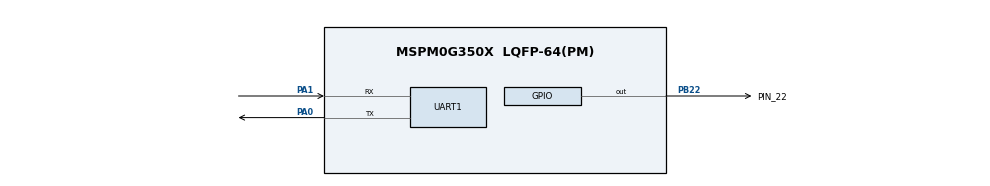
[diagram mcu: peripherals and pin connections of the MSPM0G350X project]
/**
 * @cliArgs --device "MSPM0G350X" --part "Default" --package "LQFP-64(PM)" --product "mspm0_sdk@2.04.00.06"
 * @versions {"tool":"1.22.0+3893"}
 */

/**
 * Import the modules used in this configuration.
 */
const GPIO   = scripting.addModule("/ti/driverlib/GPIO", {}, false);
const GPIO1  = GPIO.addInstance();
const GPIO2  = GPIO.addInstance();
const SYSCTL = scripting.addModule("/ti/driverlib/SYSCTL");
const TIMER  = scripting.addModule("/ti/driverlib/TIMER", {}, false);
const TIMER1 = TIMER.addInstance();
const UART   = scripting.addModule("/ti/driverlib/UART", {}, false);
const UART1  = UART.addInstance();

/**
 * Write custom configuration values to the imported modules.
 */
const divider7       = system.clockTree["PLL_PDIV"];
divider7.divideValue = 2;

const divider9       = system.clockTree["UDIV"];
divider9.divideValue = 2;

const gate7  = system.clockTree["MFCLKGATE"];
gate7.enable = true;

const multiplier2         = system.clockTree["PLL_QDIV"];
multiplier2.multiplyValue = 10;

const mux8       = system.clockTree["HSCLKMUX"];
mux8.inputSelect = "HSCLKMUX_SYSPLL0";

GPIO1.$name                              = "LED1";
GPIO1.port                               = "PORTB";
GPIO1.associatedPins[0].$name            = "PIN_22";
GPIO1.associatedPins[0].internalResistor = "PULL_DOWN";
GPIO1.associatedPins[0].assignedPin      = "22";
GPIO1.associatedPins[0].pin.$assign      = "PB22";

const Board = scripting.addModule("/ti/driverlib/Board", {}, false);

GPIO2.$name                              = "KEY";
GPIO2.port                               = "PORTB";
GPIO2.associatedPins[0].$name            = "PIN_21";
GPIO2.associatedPins[0].direction        = "INPUT";
GPIO2.associatedPins[0].internalResistor = "PULL_UP";
GPIO2.associatedPins[0].assignedPin      = "21";
GPIO2.associatedPins[0].interruptEn      = true;
GPIO2.associatedPins[0].polarity         = "RISE";

SYSCTL.forceDefaultClkConfig = true;
SYSCTL.clockTreeEn           = true;

TIMER1.$name              = "TIMER_0";
TIMER1.timerClkDiv        = 8;
TIMER1.timerStartTimer    = true;
TIMER1.interrupts         = ["ZERO"];
TIMER1.timerClkPrescale   = 250;
TIMER1.timerMode          = "PERIODIC_UP";
TIMER1.timerPeriod        = "1ms";
TIMER1.peripheral.$assign = "TIMG0";

UART1.$name                    = "UART_0";
UART1.uartClkSrc               = "MFCLK";
UART1.targetBaudRate           = 115200;
UART1.enabledInterrupts        = ["RX"];
UART1.peripheral.rxPin.$assign = "PA1";
UART1.peripheral.txPin.$assign = "PA0";
UART1.txPinConfig.$name        = "ti_driverlib_gpio_GPIOPinGeneric0";
UART1.rxPinConfig.$name        = "ti_driverlib_gpio_GPIOPinGeneric1";

/**
 * Pinmux solution for unlocked pins/peripherals. This ensures that minor changes to the automatic solver in a future
 * version of the tool will not impact the pinmux you originally saw.  These lines can be completely deleted in order to
 * re-solve from scratch.
 */
Board.peripheral.$suggestSolution            = "DEBUGSS";
Board.peripheral.swclkPin.$suggestSolution   = "PA20";
Board.peripheral.swdioPin.$suggestSolution   = "PA19";
GPIO2.associatedPins[0].pin.$suggestSolution = "PB21";
UART1.peripheral.$suggestSolution            = "UART0";
